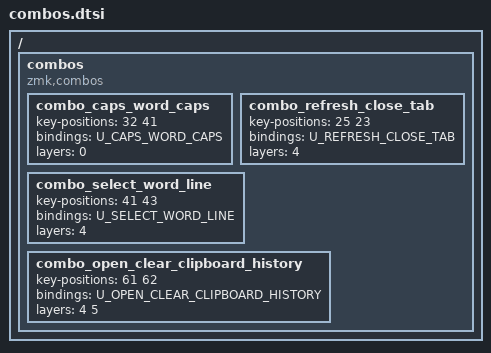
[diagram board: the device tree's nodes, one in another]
// Copyright 2022 Lukas Kucera
// https://github.com/kucera-lukas/miryoku

#include <behaviors.dtsi>
#include <dt-bindings/zmk/keys.h>

#include "caps_word.h"
#include "hold_tap.h"
#include "macros.h"

#include "caps_word.dtsi"
#include "hold_tap.dtsi"
#include "macros.dtsi"

/ {
  combos {
    compatible = "zmk,combos";

    combo_caps_word_caps {
      key-positions = <32 41>;
      bindings = <U_CAPS_WORD_CAPS>;
      layers = <0>;
    };

    combo_refresh_close_tab {
      key-positions = <25 23>;
      bindings = <U_REFRESH_CLOSE_TAB>;
      layers = <4>;
    };

    combo_select_word_line {
      key-positions = <41 43>;
      bindings = <U_SELECT_WORD_LINE>;
      layers = <4>;
    };

    combo_open_clear_clipboard_history {
      key-positions = <61 62>;
      bindings = <U_OPEN_CLEAR_CLIPBOARD_HISTORY>;
      layers = <4 5>;
    };
  };
};
